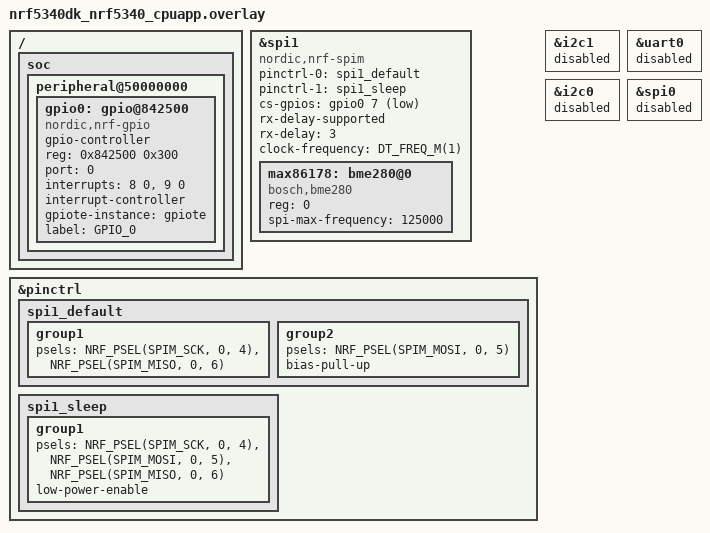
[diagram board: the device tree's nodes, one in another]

/ {
    soc {
        peripheral@50000000 {
            gpio0: gpio@842500 {
                compatible = "nordic,nrf-gpio";
                gpio-controller;
                reg = <0x842500 0x300>;
                #gpio-cells = <2>;
                status = "okay";
                port = <0>;
                interrupts = <8 0>, <9 0>;
                 #interrupt-cells = <2>;
                 interrupt-controller;
                gpiote-instance = <&gpiote>;
                label = "GPIO_0";
            };
        };
    };
};


&spi1 {
    status = "okay";
    compatible = "nordic,nrf-spim";
    pinctrl-0 = <&spi1_default>;
    pinctrl-1 = <&spi1_sleep>;
    cs-gpios = <&gpio0 7 GPIO_ACTIVE_LOW>;
    rx-delay-supported;
    rx-delay = <3>;
    clock-frequency = <DT_FREQ_M(1)>;
    pinctrl-names = "default", "sleep";
    // interrupt-parent = <&gpio0>;
    // gpio = <&gpio0 8 (GPIO_ACTIVE_LOW)>;
  ///  interrupts = <8 NRF_DEFAULT_IRQ_PRIORITY>, <9 NRF_DEFAULT_IRQ_PRIORITY>;

    // irq-gpios = <&gpio0 8 (GPIO_ACTIVE_HIGH | GPIO_PULL_DOWN)>;
    max86178: bme280@0 {
        compatible = "bosch,bme280";
        reg = <0>;
        spi-max-frequency = <125000>;
    };
    //interrupts = <9>, <NRF_DEFAULT_IRQ_PRIORITY>;
};
&pinctrl {
    spi1_default: spi1_default {
        group1 {
            psels = <NRF_PSEL(SPIM_SCK, 0, 4)>,
                    <NRF_PSEL(SPIM_MISO, 0, 6)>;
        };
        group2 {
            psels = <NRF_PSEL(SPIM_MOSI, 0, 5)>;
            bias-pull-up;
        };
    };
    spi1_sleep: spi1_sleep {
        group1 {
            psels = <NRF_PSEL(SPIM_SCK, 0, 4)>,
                    <NRF_PSEL(SPIM_MOSI, 0, 5)>,
                    <NRF_PSEL(SPIM_MISO, 0, 6)>;
            low-power-enable;
        };
    };
};
&i2c1 {
    status = "disabled";
};
&uart0 {
    status = "disabled";
};
&i2c0 {
    status = "disabled";
};
&spi0 {
    status = "disabled";
};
